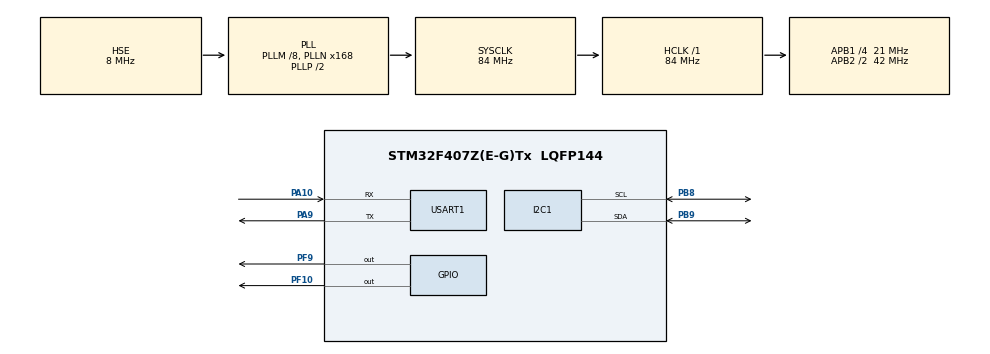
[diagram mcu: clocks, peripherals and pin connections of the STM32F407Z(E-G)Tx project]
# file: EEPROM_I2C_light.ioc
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Mcu.Family=STM32F4
Mcu.Name=STM32F407Z(E-G)Tx
Mcu.Package=LQFP144
NVIC.PriorityGroup=NVIC_PRIORITYGROUP_4
PA10.Mode=Asynchronous
PA10.Signal=USART1_RX
PA13.Mode=Serial_Wire
PA13.Signal=SYS_JTMS-SWDIO
PA14.Mode=Serial_Wire
PA14.Signal=SYS_JTCK-SWCLK
PA9.Mode=Asynchronous
PA9.Signal=USART1_TX
PB8.Mode=I2C
PB8.Signal=I2C1_SCL
PB9.Mode=I2C
PB9.Signal=I2C1_SDA
PF10.GPIO_ModeDefaultOutputPP=GPIO_MODE_OUTPUT_OD
PF10.GPIO_PuPd=GPIO_PULLUP
PF10.Signal=GPIO_Output
PF9.GPIO_ModeDefaultOutputPP=GPIO_MODE_OUTPUT_OD
PF9.GPIO_PuPd=GPIO_PULLUP
PF9.PinState=GPIO_PIN_RESET
PF9.Signal=GPIO_Output
PH0-OSC_IN.Mode=HSE-External-Oscillator
PH0-OSC_IN.Signal=RCC_OSC_IN
PH1-OSC_OUT.Mode=HSE-External-Oscillator
PH1-OSC_OUT.Signal=RCC_OSC_OUT
ProjectManager.HeapSize=0x200
ProjectManager.StackSize=0x400
ProjectManager.TargetToolchain=MDK-ARM V5.32
RCC.48MHZClocksFreq_Value=42000000
RCC.AHBFreq_Value=84000000
RCC.APB1CLKDivider=RCC_HCLK_DIV4
RCC.APB1Freq_Value=21000000
RCC.APB1TimFreq_Value=42000000
RCC.APB2CLKDivider=RCC_HCLK_DIV2
RCC.APB2Freq_Value=42000000
RCC.APB2TimFreq_Value=84000000
RCC.CortexFreq_Value=84000000
RCC.HCLKFreq_Value=84000000
RCC.HSE_VALUE=8000000
RCC.HSI_VALUE=16000000
RCC.LSE_VALUE=32768
RCC.PLLM=8
RCC.PLLN=168
RCC.PLLSourceVirtual=RCC_PLLSOURCE_HSE
RCC.SYSCLKFreq_VALUE=84000000
RCC.SYSCLKSource=RCC_SYSCLKSOURCE_PLLCLK
RCC.VCOOutputFreq_Value=168000000
USART1.Parity=PARITY_ODD
USART1.VirtualMode=VM_ASYNC
USART1.WordLength=WORDLENGTH_9B
board=custom

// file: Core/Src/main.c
/* USER CODE BEGIN Header */
/**
  ******************************************************************************
  * @file           : main.c
  * @brief          : Main program body
  ******************************************************************************
  * @attention
  *
  * Copyright (c) 2026 STMicroelectronics.
  * All rights reserved.
  *
  * This software is licensed under terms that can be found in the LICENSE file
  * in the root directory of this software component.
  * If no LICENSE file comes with this software, it is provided AS-IS.
  *
  ******************************************************************************
  */
/* USER CODE END Header */
#include "main.h"

/* USER CODE BEGIN Includes */
#include "app.h"
/* USER CODE END Includes */

I2C_HandleTypeDef hi2c1;

UART_HandleTypeDef huart1;

void SystemClock_Config(void);
static void MX_GPIO_Init(void);
static void MX_I2C1_Init(void);
static void MX_USART1_UART_Init(void);

int main(void)
{

  /* MCU Configuration--------------------------------------------------------*/

  /* Reset of all peripherals, Initializes the Flash interface and the Systick. */
  HAL_Init();

  /* Configure the system clock */
  SystemClock_Config();

  /* Initialize all configured peripherals */
  MX_GPIO_Init();
  MX_I2C1_Init();
  MX_USART1_UART_Init();
  /* USER CODE BEGIN 2 */
  BSP_Usart_Init(&huart1);
  BSP_At24c02_Init(&hi2c1);
  /* USER CODE END 2 */

  /* Infinite loop */
  /* USER CODE BEGIN WHILE */
  while (1)
  {
    APP_Run();
    /* USER CODE END WHILE */

  }
}

void SystemClock_Config(void)
{
  RCC_OscInitTypeDef RCC_OscInitStruct = {0};
  RCC_ClkInitTypeDef RCC_ClkInitStruct = {0};

  /** Configure the main internal regulator output voltage
  */
  __HAL_RCC_PWR_CLK_ENABLE();
  __HAL_PWR_VOLTAGESCALING_CONFIG(PWR_REGULATOR_VOLTAGE_SCALE1);

  /** Initializes the RCC Oscillators according to the specified parameters
  * in the RCC_OscInitTypeDef structure.
  */
  RCC_OscInitStruct.OscillatorType = RCC_OSCILLATORTYPE_HSE;
  RCC_OscInitStruct.HSEState = RCC_HSE_ON;
  RCC_OscInitStruct.PLL.PLLState = RCC_PLL_ON;
  RCC_OscInitStruct.PLL.PLLSource = RCC_PLLSOURCE_HSE;
  RCC_OscInitStruct.PLL.PLLM = 8;
  RCC_OscInitStruct.PLL.PLLN = 168;
  RCC_OscInitStruct.PLL.PLLP = RCC_PLLP_DIV2;
  RCC_OscInitStruct.PLL.PLLQ = 4;
  if (HAL_RCC_OscConfig(&RCC_OscInitStruct) != HAL_OK)
  {
    Error_Handler();
  }

  /** Initializes the CPU, AHB and APB buses clocks
  */
  RCC_ClkInitStruct.ClockType = RCC_CLOCKTYPE_HCLK|RCC_CLOCKTYPE_SYSCLK
                              |RCC_CLOCKTYPE_PCLK1|RCC_CLOCKTYPE_PCLK2;
  RCC_ClkInitStruct.SYSCLKSource = RCC_SYSCLKSOURCE_PLLCLK;
  RCC_ClkInitStruct.AHBCLKDivider = RCC_SYSCLK_DIV1;
  RCC_ClkInitStruct.APB1CLKDivider = RCC_HCLK_DIV4;
  RCC_ClkInitStruct.APB2CLKDivider = RCC_HCLK_DIV2;

  if (HAL_RCC_ClockConfig(&RCC_ClkInitStruct, FLASH_LATENCY_2) != HAL_OK)
  {
    Error_Handler();
  }
}

static void MX_I2C1_Init(void)
{

  hi2c1.Instance = I2C1;
  hi2c1.Init.ClockSpeed = 100000;
  hi2c1.Init.DutyCycle = I2C_DUTYCYCLE_2;
  hi2c1.Init.OwnAddress1 = 0;
  hi2c1.Init.AddressingMode = I2C_ADDRESSINGMODE_7BIT;
  hi2c1.Init.DualAddressMode = I2C_DUALADDRESS_DISABLE;
  hi2c1.Init.OwnAddress2 = 0;
  hi2c1.Init.GeneralCallMode = I2C_GENERALCALL_DISABLE;
  hi2c1.Init.NoStretchMode = I2C_NOSTRETCH_DISABLE;
  if (HAL_I2C_Init(&hi2c1) != HAL_OK)
  {
    Error_Handler();
  }

}

static void MX_USART1_UART_Init(void)
{

  huart1.Instance = USART1;
  huart1.Init.BaudRate = 115200;
  huart1.Init.WordLength = UART_WORDLENGTH_9B;
  huart1.Init.StopBits = UART_STOPBITS_1;
  huart1.Init.Parity = UART_PARITY_ODD;
  huart1.Init.Mode = UART_MODE_TX_RX;
  huart1.Init.HwFlowCtl = UART_HWCONTROL_NONE;
  huart1.Init.OverSampling = UART_OVERSAMPLING_16;
  if (HAL_UART_Init(&huart1) != HAL_OK)
  {
    Error_Handler();
  }

}

static void MX_GPIO_Init(void)
{
  GPIO_InitTypeDef GPIO_InitStruct = {0};

  /* GPIO Ports Clock Enable */
  __HAL_RCC_GPIOF_CLK_ENABLE();
  __HAL_RCC_GPIOH_CLK_ENABLE();
  __HAL_RCC_GPIOA_CLK_ENABLE();
  __HAL_RCC_GPIOB_CLK_ENABLE();

  /*Configure GPIO pin Output Level */
  HAL_GPIO_WritePin(GPIOF, GPIO_PIN_9|GPIO_PIN_10, GPIO_PIN_RESET);

  /*Configure GPIO pins : PF9 PF10 */
  GPIO_InitStruct.Pin = GPIO_PIN_9|GPIO_PIN_10;
  GPIO_InitStruct.Mode = GPIO_MODE_OUTPUT_OD;
  GPIO_InitStruct.Pull = GPIO_PULLUP;
  GPIO_InitStruct.Speed = GPIO_SPEED_FREQ_LOW;
  HAL_GPIO_Init(GPIOF, &GPIO_InitStruct);

}

void Error_Handler(void)
{
  __disable_irq();
  while (1)
  {
  }
}
